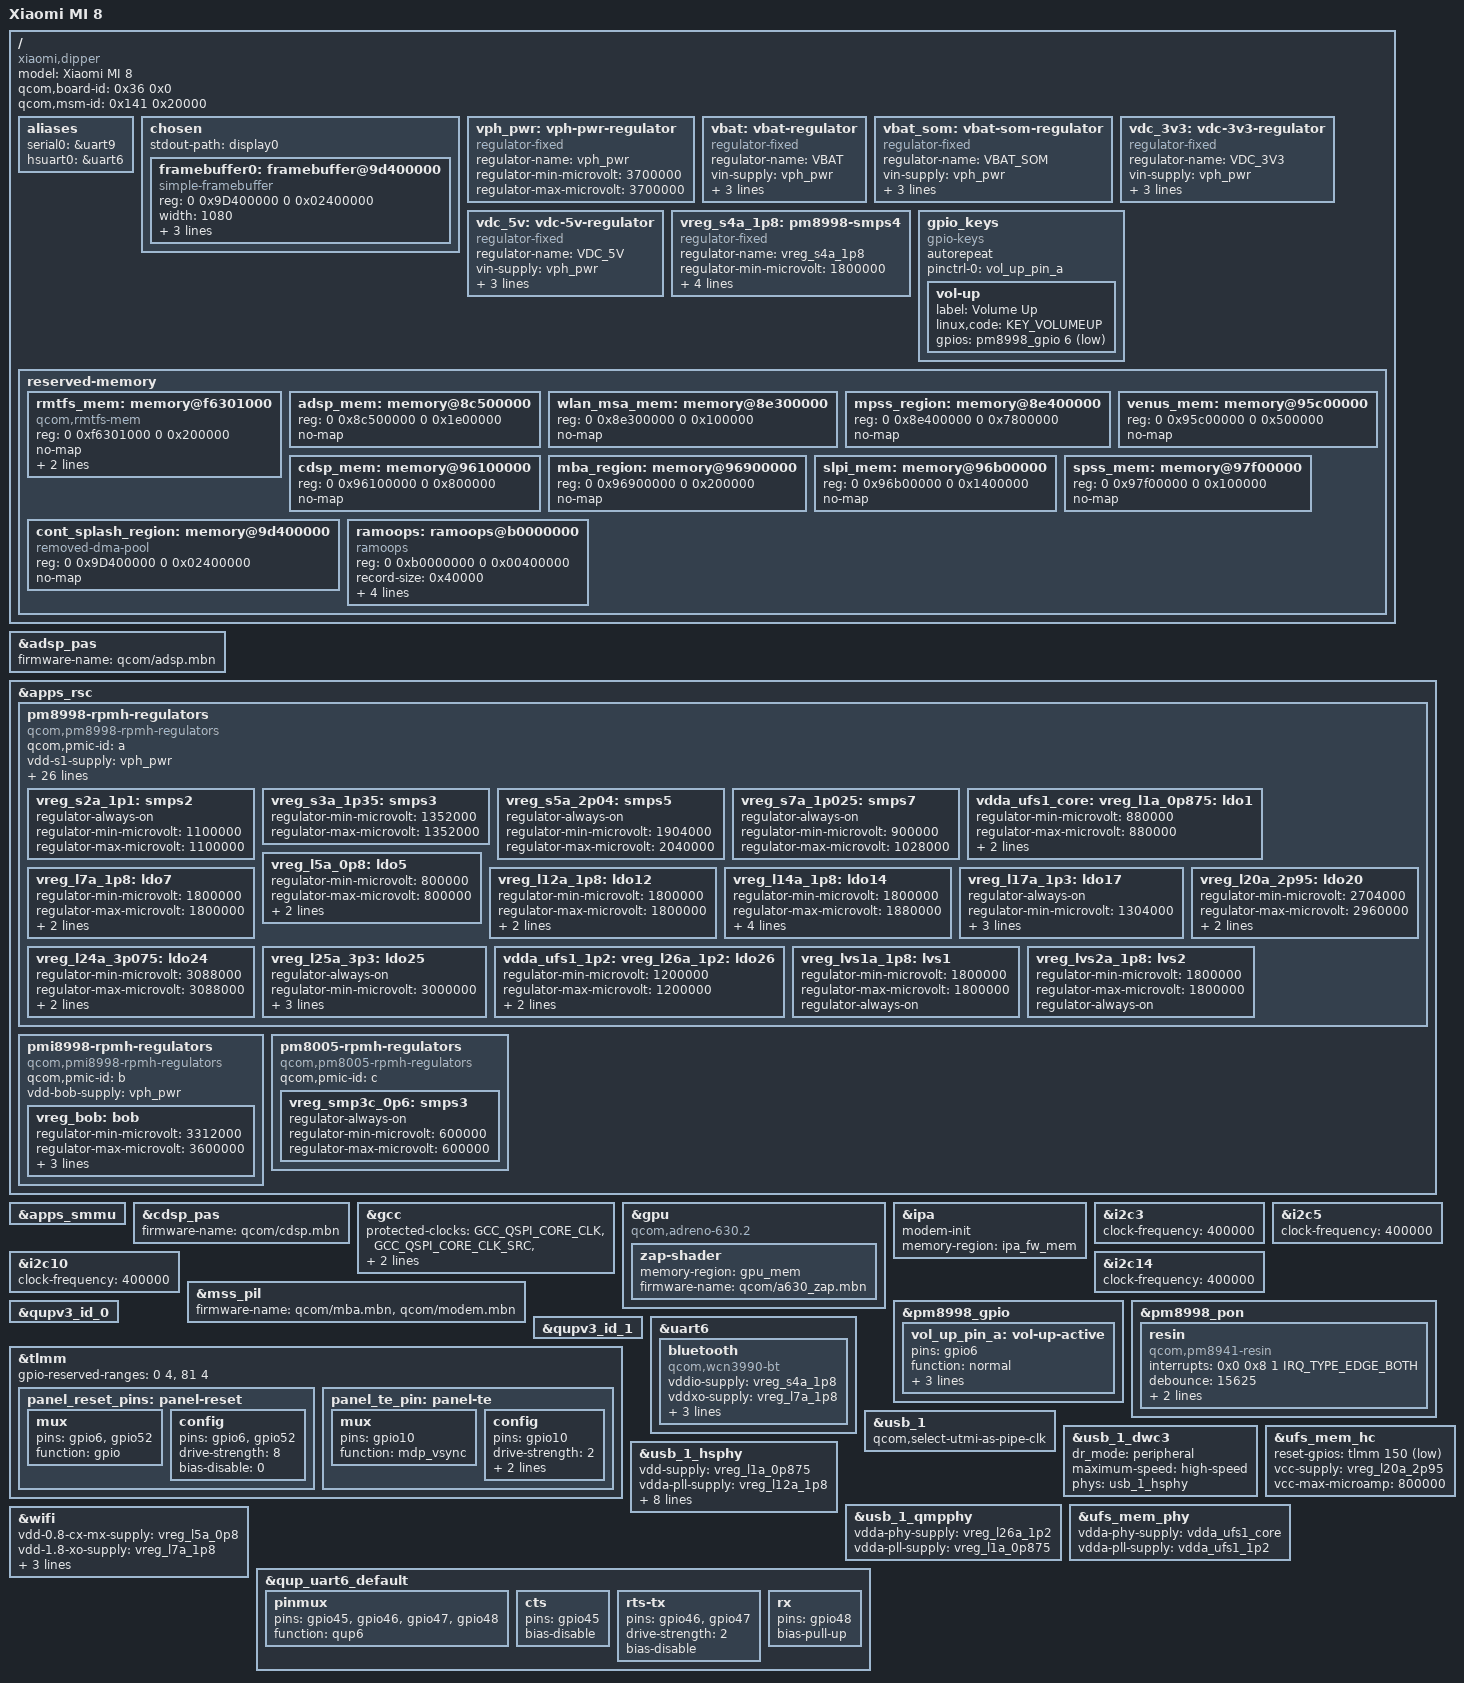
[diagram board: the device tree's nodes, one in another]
// SPDX-License-Identifier: GPL-2.0
/*
 * Copyright (c) 2020, Sophon Wu <strongtz@yeah.net>
 */

/dts-v1/;

#include <dt-bindings/gpio/gpio.h>
#include <dt-bindings/pinctrl/qcom,pmic-gpio.h>
#include <dt-bindings/regulator/qcom,rpmh-regulator.h>
#include "sdm845.dtsi"
#include "pm8998.dtsi"
#include "pmi8998.dtsi"
#include "pm8005.dtsi"

/ {
	model = "Xiaomi MI 8";
	compatible = "xiaomi,dipper", "qcom,sdm845";
	/* required for bootloader to select correct board */
	qcom,board-id = <0x36 0x0>;
	qcom,msm-id = <0x141 0x20000>;

	aliases {
		serial0 = &uart9;
		hsuart0 = &uart6;
	};

	chosen {
		#address-cells = <2>;
		#size-cells = <2>;
		ranges;

		// For simplefb hack
		stdout-path = "display0";

		/* hack: use framebuffer setup by bootloader.
		 * the address is taken from the bootloader config (strings xbl.img | grep "Display Reserved")
		 */
		framebuffer0: framebuffer@9d400000 {
			compatible = "simple-framebuffer";
			reg = <0 0x9D400000 0 0x02400000>;
			width = <1080>;
			height = <2248>;
			stride = <(1080 * 4)>;
			format = "a8r8g8b8";
			status = "okay";
		};
	};

	vph_pwr: vph-pwr-regulator {
		compatible = "regulator-fixed";
		regulator-name = "vph_pwr";
		regulator-min-microvolt = <3700000>;
		regulator-max-microvolt = <3700000>;
	};

	vbat: vbat-regulator {
		compatible = "regulator-fixed";
		regulator-name = "VBAT";

		vin-supply = <&vph_pwr>;
		regulator-min-microvolt = <4200000>;
		regulator-max-microvolt = <4200000>;
		regulator-always-on;
	};

	vbat_som: vbat-som-regulator {
		compatible = "regulator-fixed";
		regulator-name = "VBAT_SOM";

		vin-supply = <&vph_pwr>;
		regulator-min-microvolt = <4200000>;
		regulator-max-microvolt = <4200000>;
		regulator-always-on;
	};

	vdc_3v3: vdc-3v3-regulator {
		compatible = "regulator-fixed";
		regulator-name = "VDC_3V3";
		vin-supply = <&vph_pwr>;
		regulator-min-microvolt = <3300000>;
		regulator-max-microvolt = <3300000>;
		regulator-always-on;
	};

	vdc_5v: vdc-5v-regulator {
		compatible = "regulator-fixed";
		regulator-name = "VDC_5V";

		vin-supply = <&vph_pwr>;
		regulator-min-microvolt = <500000>;
		regulator-max-microvolt = <500000>;
		regulator-always-on;
	};

	/*
	 * Apparently RPMh does not provide support for PM8998 S4 because it
	 * is always-on; model it as a fixed regulator.
	 */
	vreg_s4a_1p8: pm8998-smps4 {
		compatible = "regulator-fixed";
		regulator-name = "vreg_s4a_1p8";
		regulator-min-microvolt = <1800000>;
		regulator-max-microvolt = <1800000>;
		regulator-always-on;
		regulator-boot-on;
		vin-supply = <&vph_pwr>;
	};


	gpio_keys {
		compatible = "gpio-keys";
		autorepeat;

		pinctrl-names = "default";
		pinctrl-0 = <&vol_up_pin_a>;

		vol-up {
			label = "Volume Up";
			linux,code = <KEY_VOLUMEUP>;
			gpios = <&pm8998_gpio 6 GPIO_ACTIVE_LOW>;
		};
	};
};

&adsp_pas {
	status = "okay";
	firmware-name = "qcom/adsp.mbn";
};

&apps_rsc {
	pm8998-rpmh-regulators {
		compatible = "qcom,pm8998-rpmh-regulators";
		qcom,pmic-id = "a";
		vdd-s1-supply = <&vph_pwr>;
		vdd-s2-supply = <&vph_pwr>;
		vdd-s3-supply = <&vph_pwr>;
		vdd-s4-supply = <&vph_pwr>;
		vdd-s5-supply = <&vph_pwr>;
		vdd-s6-supply = <&vph_pwr>;
		vdd-s7-supply = <&vph_pwr>;
		vdd-s8-supply = <&vph_pwr>;
		vdd-s9-supply = <&vph_pwr>;
		vdd-s10-supply = <&vph_pwr>;
		vdd-s11-supply = <&vph_pwr>;
		vdd-s12-supply = <&vph_pwr>;
		vdd-s13-supply = <&vph_pwr>;
		vdd-l1-l27-supply = <&vreg_s7a_1p025>;
		vdd-l2-l8-l17-supply = <&vreg_s3a_1p35>;
		vdd-l3-l11-supply = <&vreg_s7a_1p025>;
		vdd-l4-l5-supply = <&vreg_s7a_1p025>;
		vdd-l6-supply = <&vph_pwr>;
		vdd-l7-l12-l14-l15-supply = <&vreg_s5a_2p04>;
		vdd-l9-supply = <&vreg_bob>;
		vdd-l10-l23-l25-supply = <&vreg_bob>;
		vdd-l13-l19-l21-supply = <&vreg_bob>;
		vdd-l16-l28-supply = <&vreg_bob>;
		vdd-l18-l22-supply = <&vreg_bob>;
		vdd-l20-l24-supply = <&vreg_bob>;
		vdd-l26-supply = <&vreg_s3a_1p35>;
		vin-lvs-1-2-supply = <&vreg_s4a_1p8>;

		vreg_s2a_1p1: smps2 {
			regulator-always-on;
			regulator-min-microvolt = <1100000>;
			regulator-max-microvolt = <1100000>;
		};

		vreg_s3a_1p35: smps3 {
			regulator-min-microvolt = <1352000>;
			regulator-max-microvolt = <1352000>;
		};

		// vreg_s4a_1p8: smps4 {
		// 	regulator-min-microvolt = <1800000>;
		// 	regulator-max-microvolt = <1800000>;
		// };

		vreg_s5a_2p04: smps5 {
			regulator-always-on;
			regulator-min-microvolt = <1904000>;
			regulator-max-microvolt = <2040000>;
		};

		vreg_s7a_1p025: smps7 {
			regulator-always-on;
			regulator-min-microvolt = <900000>;
			regulator-max-microvolt = <1028000>;
		};

		vdda_ufs1_core:
		vreg_l1a_0p875: ldo1 {
			regulator-min-microvolt = <880000>;
			regulator-max-microvolt = <880000>;
			regulator-initial-mode = <RPMH_REGULATOR_MODE_HPM>;
		};

		// vreg_l2a_0p875: ldo2 {
		// 	regulator-min-microvolt = <1200000>;
		// 	regulator-max-microvolt = <1200000>;
		// 	regulator-initial-mode = <RPMH_REGULATOR_MODE_HPM>;
		// 	regulator-always-on;
		// };

		// vreg_l3a_0p875: ldo3 {
		// 	regulator-min-microvolt = <1000000>;
		// 	regulator-max-microvolt = <1000000>;
		// 	regulator-initial-mode = <RPMH_REGULATOR_MODE_HPM>;
		// };

		vreg_l5a_0p8: ldo5 {
			regulator-min-microvolt = <800000>;
			regulator-max-microvolt = <800000>;
			regulator-initial-mode = <RPMH_REGULATOR_MODE_HPM>;
		};

		// vreg_l6a_1p8: ldo6 {
		// 	regulator-min-microvolt = <1856000>;
		// 	regulator-max-microvolt = <1856000>;
		// 	regulator-initial-mode = <RPMH_REGULATOR_MODE_HPM>;
		// };

		vreg_l7a_1p8: ldo7 {
			regulator-min-microvolt = <1800000>;
			regulator-max-microvolt = <1800000>;
			regulator-initial-mode = <RPMH_REGULATOR_MODE_HPM>;
		};

		// vreg_l8a_1p2: ldo8 {
		// 	regulator-min-microvolt = <1200000>;
		// 	regulator-max-microvolt = <1248000>;
		// 	regulator-initial-mode = <RPMH_REGULATOR_MODE_HPM>;
		// };

		// vreg_l9a_2p95: ldo9 {
		// 	regulator-min-microvolt = <1704000>;
		// 	regulator-max-microvolt = <2928000>;
		// 	regulator-initial-mode = <RPMH_REGULATOR_MODE_HPM>;
		// };

		// vreg_l10a_2p95: ldo10 {
		// 	regulator-min-microvolt = <1704000>;
		// 	regulator-max-microvolt = <2928000>;
		// 	regulator-initial-mode = <RPMH_REGULATOR_MODE_HPM>;
		// };

		// vreg_l11a_1p05: ldo11 {
		// 	regulator-min-microvolt = <1000000>;
		// 	regulator-max-microvolt = <1048000>;
		// 	regulator-initial-mode = <RPMH_REGULATOR_MODE_HPM>;
		// };

		vreg_l12a_1p8: ldo12 {
			regulator-min-microvolt = <1800000>;
			regulator-max-microvolt = <1800000>;
			regulator-initial-mode = <RPMH_REGULATOR_MODE_HPM>;
		};

		// vreg_l13a_2p95: ldo13 {
		// 	regulator-min-microvolt = <1800000>;
		// 	regulator-max-microvolt = <2960000>;
		// 	regulator-initial-mode = <RPMH_REGULATOR_MODE_HPM>;
		// };


		// dsi and touchscreen maybe
		vreg_l14a_1p8: ldo14 {
			regulator-min-microvolt = <1800000>;
			regulator-max-microvolt = <1880000>;
			regulator-always-on;
			regulator-boot-on;
			regulator-initial-mode = <RPMH_REGULATOR_MODE_HPM>;
		};

		// vreg_l15a_1p8: ldo15 {
		// 	regulator-min-microvolt = <1800000>;
		// 	regulator-max-microvolt = <1800000>;
		// 	regulator-initial-mode = <RPMH_REGULATOR_MODE_HPM>;
		// };

		// vreg_l16a_2p7: ldo16 {
		// 	regulator-min-microvolt = <2704000>;
		// 	regulator-max-microvolt = <2704000>;
		// 	regulator-initial-mode = <RPMH_REGULATOR_MODE_HPM>;
		// };

		vreg_l17a_1p3: ldo17 {
			regulator-always-on;
			regulator-min-microvolt = <1304000>;
			regulator-max-microvolt = <1304000>;
			regulator-initial-mode = <RPMH_REGULATOR_MODE_HPM>;
		};

		// vreg_l18a_2p9: ldo18 {
		// 	regulator-min-microvolt = <2704000>;
		// 	regulator-max-microvolt = <2960000>;
		// 	regulator-initial-mode = <RPMH_REGULATOR_MODE_HPM>;
		// };

		// vreg_l19a_3p1: ldo19 {
		// 	regulator-min-microvolt = <2856000>;
		// 	regulator-max-microvolt = <3104000>;
		// 	regulator-initial-mode = <RPMH_REGULATOR_MODE_HPM>;
		// };

		vreg_l20a_2p95: ldo20 {
			regulator-min-microvolt = <2704000>;
			regulator-max-microvolt = <2960000>;
			regulator-initial-mode = <RPMH_REGULATOR_MODE_HPM>;
		};

		// vreg_l21a_2p95: ldo21 {
		// 	regulator-min-microvolt = <2704000>;
		// 	regulator-max-microvolt = <2960000>;
		// 	regulator-initial-mode = <RPMH_REGULATOR_MODE_HPM>;
		// };

		// vreg_l22a_3p3: ldo22 {
		// 	regulator-min-microvolt = <2864000>;
		// 	regulator-max-microvolt = <3312000>;
		// 	regulator-initial-mode = <RPMH_REGULATOR_MODE_HPM>;
		// };

		// vreg_l23a_3p3: ldo23 {
		// 	regulator-min-microvolt = <3000000>;
		// 	regulator-max-microvolt = <3312000>;
		// 	regulator-initial-mode = <RPMH_REGULATOR_MODE_HPM>;
		// };

		vreg_l24a_3p075: ldo24 {
			regulator-min-microvolt = <3088000>;
			regulator-max-microvolt = <3088000>;
			regulator-initial-mode = <RPMH_REGULATOR_MODE_HPM>;
		};

		vreg_l25a_3p3: ldo25 {
			regulator-always-on;
			regulator-min-microvolt = <3000000>;
			regulator-max-microvolt = <3312000>;
			regulator-initial-mode = <RPMH_REGULATOR_MODE_HPM>;
		};

		vdda_ufs1_1p2:
		vreg_l26a_1p2: ldo26 {
			regulator-min-microvolt = <1200000>;
			regulator-max-microvolt = <1200000>;
			regulator-initial-mode = <RPMH_REGULATOR_MODE_HPM>;
		};

		vreg_lvs1a_1p8: lvs1 {
			regulator-min-microvolt = <1800000>;
			regulator-max-microvolt = <1800000>;
			regulator-always-on;
		};

		vreg_lvs2a_1p8: lvs2 {
			regulator-min-microvolt = <1800000>;
			regulator-max-microvolt = <1800000>;
			regulator-always-on;
		};
	};

	pmi8998-rpmh-regulators {
		compatible = "qcom,pmi8998-rpmh-regulators";
		qcom,pmic-id = "b";

		vdd-bob-supply = <&vph_pwr>;

		vreg_bob: bob {
			regulator-min-microvolt = <3312000>;
			regulator-max-microvolt = <3600000>;
			regulator-initial-mode = <RPMH_REGULATOR_MODE_AUTO>;
			regulator-allow-bypass;
		};
	};

	pm8005-rpmh-regulators {
		compatible = "qcom,pm8005-rpmh-regulators";
		qcom,pmic-id = "c";

		vreg_smp3c_0p6: smps3 {
			regulator-always-on;
			regulator-min-microvolt = <600000>;
			regulator-max-microvolt = <600000>;
		};
	};
};

&apps_smmu {
	/* Enable this when upstream smmu driver gets patched */
	status = "okay";
};

&cdsp_pas {
	status = "okay";
	firmware-name = "qcom/cdsp.mbn";
};




// vreg_l14a_1p8

// &dsi0 {
// 	status = "okay";
// 	vdda-supply = <&vreg_l26a_1p2>;

// 	#address-cells = <1>;
// 	#size-cells = <0>;

// 	display_panel: panel@0 {
// 		status = "disabled";

// 		port {
// 			panel_in: endpoint {
// 				remote-endpoint = <&dsi0_out>;
// 			};
// 		};
// 	};
// };

// &dsi0_out {
// 	remote-endpoint = <&panel_in>;
// 	data-lanes = <0 1 2 3>;
// };

// &dsi0_phy {
// 	status = "okay";
// 	vdds-supply = <&vreg_l1a_0p875>;
// };

// &display_panel {
// 	compatible = "visionox,fhd-r66455";
// 	status = "okay";

// 	#address-cells = <1>;
// 	#size-cells = <0>;
// 	reg = <0>;

// 	vddio-supply = <&vreg_l14a_1p8>;

// 	reset-gpios = <&tlmm 6 GPIO_ACTIVE_HIGH>;

// 	pinctrl-names = "default";
// 	pinctrl-0 = <&panel_reset_pins &panel_te_pin>;
// };




&gcc {
	protected-clocks = <GCC_QSPI_CORE_CLK>,
			   <GCC_QSPI_CORE_CLK_SRC>,
			   <GCC_QSPI_CNOC_PERIPH_AHB_CLK>,
			   <GCC_LPASS_Q6_AXI_CLK>,
			   <GCC_LPASS_SWAY_CLK>;
};

&gpu {
	/*
	 * note: the amd,imageon compatible makes it possible
	 * to use the drm/msm driver without the display node,
	 * make sure to remove it when display node is added
	 */
	compatible = "qcom,adreno-630.2",
				 "qcom,adreno",
				 "amd,imageon";
	zap-shader {
		memory-region = <&gpu_mem>;
		firmware-name = "qcom/a630_zap.mbn";
	};
};

&ipa {
	status = "okay";
	modem-init;
	memory-region = <&ipa_fw_mem>;
};

/* NFC */
&i2c3 {
	status = "okay";
	clock-frequency = <400000>;
};

/* Audio Amplifier tas2557 */
&i2c5 {
	status = "okay";
	clock-frequency = <400000>;
};

/* smb1355 and lm3644 LED */
&i2c10 {
	status = "okay";
	clock-frequency = <400000>;
};

/* fts touchscreen */
&i2c14 {
	status = "okay";
	clock-frequency = <400000>;
};

// &mdss {
// 	status = "okay";
// };

// &mdss_mdp {
// 	status = "okay";
// };

&mss_pil {
	status = "okay";
	firmware-name = "qcom/mba.mbn", "qcom/modem.mbn";
};

&pm8998_gpio {
	vol_up_pin_a: vol-up-active {
		pins = "gpio6";
		function = "normal";
		input-enable;
		bias-pull-up;
		qcom,drive-strength = <PMIC_GPIO_STRENGTH_NO>;
	};
};

&pm8998_pon {
	resin {
		compatible = "qcom,pm8941-resin";
		interrupts = <0x0 0x8 1 IRQ_TYPE_EDGE_BOTH>;
		debounce = <15625>;
		bias-pull-up;
		linux,code = <KEY_VOLUMEDOWN>;
	};
};

&qupv3_id_0 {
	status = "okay";
};

&qupv3_id_1 {
	status = "okay";
};

&tlmm {
	gpio-reserved-ranges = <0 4>, <81 4>;

	panel_reset_pins: panel-reset {
		mux {
			pins = "gpio6", "gpio52";
			function = "gpio";
		};

		config {
			pins = "gpio6", "gpio52";
			drive-strength = <8>;
			bias-disable = <0>;
		};
	};

	panel_te_pin: panel-te {
		mux {
			pins = "gpio10";
			function = "mdp_vsync";
		};

		config {
			pins = "gpio10";
			drive-strength = <2>;
			bias-disable;
			input-enable;
		};
	};
};

&uart6 {
	status = "okay";

	bluetooth {
		compatible = "qcom,wcn3990-bt";
		vddio-supply = <&vreg_s4a_1p8>;
		vddxo-supply = <&vreg_l7a_1p8>;
		vddrf-supply = <&vreg_l17a_1p3>;
		vddch0-supply = <&vreg_l25a_3p3>;
		max-speed = <3200000>;
	};
};


&usb_1 {
	status = "okay";
	/* We'll use this as USB 2.0 only */
	qcom,select-utmi-as-pipe-clk;
};

&usb_1_dwc3 {
	dr_mode = "peripheral";

	/* fastest mode for USB 2 */
	maximum-speed = "high-speed";

	/* Remove USB3 phy */
	phys = <&usb_1_hsphy>;
	phy-names = "usb2-phy";
};

&usb_1_hsphy {
	status = "okay";

	vdd-supply = <&vreg_l1a_0p875>;
	vdda-pll-supply = <&vreg_l12a_1p8>;
	vdda-phy-dpdm-supply = <&vreg_l24a_3p075>;

	qcom,imp-res-offset-value = <8>;
	qcom,hstx-trim-value = <QUSB2_V2_HSTX_TRIM_21_6_MA>;
	qcom,preemphasis-level = <QUSB2_V2_PREEMPHASIS_5_PERCENT>;
	qcom,preemphasis-width = <QUSB2_V2_PREEMPHASIS_WIDTH_HALF_BIT>;
};

&usb_1_qmpphy {
	status = "okay";

	vdda-phy-supply = <&vreg_l26a_1p2>;
	vdda-pll-supply = <&vreg_l1a_0p875>;
};


&ufs_mem_hc {
	status = "okay";
	reset-gpios = <&tlmm 150 GPIO_ACTIVE_LOW>;
	vcc-supply = <&vreg_l20a_2p95>;
	vcc-max-microamp = <800000>;
};

&ufs_mem_phy {
	status = "okay";
	vdda-phy-supply = <&vdda_ufs1_core>;
	vdda-pll-supply = <&vdda_ufs1_1p2>;
};

&wifi {
	status = "okay";

	vdd-0.8-cx-mx-supply = <&vreg_l5a_0p8>;
	vdd-1.8-xo-supply = <&vreg_l7a_1p8>;
	vdd-1.3-rfa-supply = <&vreg_l17a_1p3>;
	vdd-3.3-ch0-supply = <&vreg_l25a_3p3>;

	qcom,snoc-host-cap-8bit-quirk;
};

/* PINCTRL - additions to nodes defined in sdm845.dtsi */

&qup_uart6_default {
	pinmux {
		 pins = "gpio45", "gpio46", "gpio47", "gpio48";
		 function = "qup6";
	};

	cts {
		pins = "gpio45";
		bias-disable;
	};

	rts-tx {
		pins = "gpio46", "gpio47";
		drive-strength = <2>;
		bias-disable;
	};

	rx {
		pins = "gpio48";
		bias-pull-up;
	};
};

/* Reserved memory changes */
/*
 * The memory regions related to the modem have to be changed 
 * according to the adresses in downstream as
 * the modem is hard-coded to expect these regions to be at those adresses.
 * 
 */
/delete-node/ &rmtfs_mem;
/delete-node/ &adsp_mem;
/delete-node/ &wlan_msa_mem;
/delete-node/ &mpss_region;
/delete-node/ &venus_mem;
/delete-node/ &cdsp_mem;
/delete-node/ &mba_region;
/delete-node/ &slpi_mem;
/delete-node/ &spss_mem;

/ {
	reserved-memory {
		rmtfs_mem: memory@f6301000 {
			compatible = "qcom,rmtfs-mem";
			reg = <0 0xf6301000 0 0x200000>;
			no-map;

			qcom,client-id = <1>;
			qcom,vmid = <15>;
		};

		adsp_mem: memory@8c500000 {
			reg = <0 0x8c500000 0 0x1e00000>;
			no-map;
		};

		wlan_msa_mem: memory@8e300000 {
			reg = <0 0x8e300000 0 0x100000>;
			no-map;
		};

		mpss_region: memory@8e400000 {
			reg = <0 0x8e400000 0 0x7800000>;
			no-map;
		};

		venus_mem: memory@95c00000 {
			reg = <0 0x95c00000 0 0x500000>;
			no-map;
		};

		cdsp_mem: memory@96100000 {
			reg = <0 0x96100000 0 0x800000>;
			no-map;
		};

		mba_region: memory@96900000 {
			reg = <0 0x96900000 0 0x200000>;
			no-map;
		};

		slpi_mem: memory@96b00000 {
			reg = <0 0x96b00000 0 0x1400000>;
			no-map;
		};

		spss_mem: memory@97f00000 {
			reg = <0 0x97f00000 0 0x100000>;
			no-map;
		};

		/* hack: bootloader framebuffer */
		cont_splash_region: memory@9d400000 {
			compatible = "removed-dma-pool";
			reg = <0 0x9D400000 0 0x02400000>;
			no-map;
		};

		ramoops: ramoops@b0000000 {
			compatible = "ramoops";
			reg = <0 0xb0000000 0 0x00400000>;
			record-size = <0x40000>; /*256x1024*/
			console-size = <0x40000>;
			ftrace-size = <0x40000>;
			pmsg-size = <0x200000>;
			ecc-size = <0x0>;
		};

	};
};
